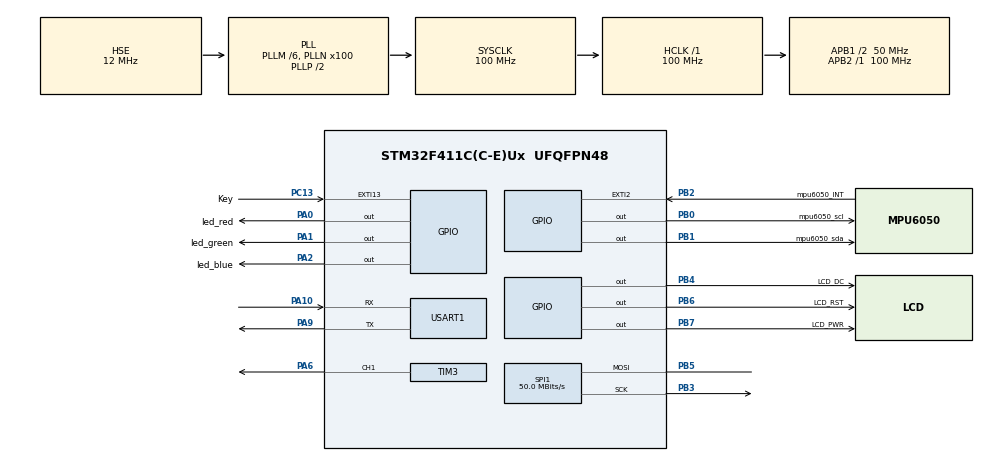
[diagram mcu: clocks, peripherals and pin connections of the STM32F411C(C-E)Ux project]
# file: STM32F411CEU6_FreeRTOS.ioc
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Dma.Request0=TIM3_CH1/TRIG
Dma.Request1=SPI1_TX
Dma.SPI1_TX.1.Direction=DMA_MEMORY_TO_PERIPH
Dma.SPI1_TX.1.FIFOMode=DMA_FIFOMODE_DISABLE
Dma.SPI1_TX.1.Instance=DMA2_Stream2
Dma.SPI1_TX.1.MemDataAlignment=DMA_MDATAALIGN_BYTE
Dma.SPI1_TX.1.MemInc=DMA_MINC_ENABLE
Dma.SPI1_TX.1.Mode=DMA_NORMAL
Dma.SPI1_TX.1.PeriphDataAlignment=DMA_PDATAALIGN_BYTE
Dma.SPI1_TX.1.PeriphInc=DMA_PINC_DISABLE
Dma.SPI1_TX.1.Priority=DMA_PRIORITY_LOW
Dma.TIM3_CH1/TRIG.0.Direction=DMA_MEMORY_TO_PERIPH
Dma.TIM3_CH1/TRIG.0.FIFOMode=DMA_FIFOMODE_DISABLE
Dma.TIM3_CH1/TRIG.0.Instance=DMA1_Stream4
Dma.TIM3_CH1/TRIG.0.MemDataAlignment=DMA_MDATAALIGN_WORD
Dma.TIM3_CH1/TRIG.0.MemInc=DMA_MINC_ENABLE
Dma.TIM3_CH1/TRIG.0.Mode=DMA_NORMAL
Dma.TIM3_CH1/TRIG.0.PeriphDataAlignment=DMA_PDATAALIGN_WORD
Dma.TIM3_CH1/TRIG.0.PeriphInc=DMA_PINC_DISABLE
Dma.TIM3_CH1/TRIG.0.Priority=DMA_PRIORITY_LOW
FREERTOS.Tasks01=Task_LED_Red,24,128,AppTask_LED_Red,Default,NULL,Dynamic,NULL,NULL;Task_LED_Green,8,128,AppTask_LED_Green,Default,NULL,Dynamic,NULL,NULL
Mcu.Family=STM32F4
Mcu.Name=STM32F411C(C-E)Ux
Mcu.Package=UFQFPN48
NVIC.DMA1_Stream4_IRQn=true\:5\:0\:false\:false\:true\:true\:false\:true\:true
NVIC.DMA2_Stream2_IRQn=true\:5\:0\:false\:false\:true\:true\:false\:true\:true
NVIC.EXTI15_10_IRQn=true\:6\:0\:true\:false\:true\:true\:true\:true\:true
NVIC.EXTI2_IRQn=true\:6\:0\:true\:false\:true\:true\:true\:true\:true
NVIC.PriorityGroup=NVIC_PRIORITYGROUP_4
NVIC.TIM1_TRG_COM_TIM11_IRQn=true\:5\:0\:false\:false\:true\:true\:true\:true\:true
NVIC.TIM4_IRQn=true\:0\:0\:false\:false\:true\:false\:false\:true\:true
NVIC.TimeBase=TIM4_IRQn
NVIC.TimeBaseIP=TIM4
PA0-WKUP.GPIO_Label=led_red
PA0-WKUP.GPIO_PuPd=GPIO_PULLUP
PA0-WKUP.PinState=GPIO_PIN_SET
PA0-WKUP.Signal=GPIO_Output
PA1.GPIO_Label=led_green
PA1.GPIO_ModeDefaultOutputPP=GPIO_MODE_OUTPUT_PP
PA1.GPIO_PuPd=GPIO_PULLUP
PA1.PinState=GPIO_PIN_SET
PA1.Signal=GPIO_Output
PA10.Mode=Asynchronous
PA10.Signal=USART1_RX
PA13.Mode=Serial_Wire
PA13.Signal=SYS_JTMS-SWDIO
PA14.Mode=Serial_Wire
PA14.Signal=SYS_JTCK-SWCLK
PA2.GPIO_Label=led_blue
PA2.GPIO_PuPd=GPIO_PULLUP
PA2.PinState=GPIO_PIN_SET
PA2.Signal=GPIO_Output
PA6.Signal=S_TIM3_CH1
PA9.Mode=Asynchronous
PA9.Signal=USART1_TX
PB0.GPIO_Label=mpu6050_scl
PB0.GPIO_ModeDefaultOutputPP=GPIO_MODE_OUTPUT_PP
PB0.GPIO_PuPd=GPIO_PULLUP
PB0.GPIO_Speed=GPIO_SPEED_FREQ_VERY_HIGH
PB0.PinState=GPIO_PIN_RESET
PB0.Signal=GPIO_Output
PB1.GPIO_Label=mpu6050_sda
PB1.GPIO_ModeDefaultOutputPP=GPIO_MODE_OUTPUT_OD
PB1.GPIO_PuPd=GPIO_PULLUP
PB1.GPIO_Speed=GPIO_SPEED_FREQ_VERY_HIGH
PB1.PinState=GPIO_PIN_RESET
PB1.Signal=GPIO_Output
PB2.GPIO_Label=mpu6050_INT
PB2.Signal=GPXTI2
PB3.Mode=Simplex_Bidirectional_Master
PB3.Signal=SPI1_SCK
PB4.GPIO_Label=LCD_DC
PB4.Signal=GPIO_Output
PB5.Mode=Simplex_Bidirectional_Master
PB5.Signal=SPI1_MOSI
PB6.GPIO_Label=LCD_RST
PB6.Signal=GPIO_Output
PB7.GPIO_Label=LCD_PWR
PB7.Signal=GPIO_Output
PC13-ANTI_TAMP.GPIO_Label=Key
PC13-ANTI_TAMP.GPIO_ModeDefaultEXTI=GPIO_MODE_IT_FALLING
PC13-ANTI_TAMP.GPIO_PuPd=GPIO_PULLUP
PC13-ANTI_TAMP.Signal=GPXTI13
PH0\ -\ OSC_IN.Mode=HSE-External-Oscillator
PH0\ -\ OSC_IN.Signal=RCC_OSC_IN
PH1\ -\ OSC_OUT.Mode=HSE-External-Oscillator
PH1\ -\ OSC_OUT.Signal=RCC_OSC_OUT
ProjectManager.HeapSize=0x200
ProjectManager.StackSize=0x400
ProjectManager.TargetToolchain=MDK-ARM V5.27
RCC.48MHZClocksFreq_Value=50000000
RCC.AHBFreq_Value=100000000
RCC.APB1CLKDivider=RCC_HCLK_DIV2
RCC.APB1Freq_Value=50000000
RCC.APB1TimFreq_Value=100000000
RCC.APB2Freq_Value=100000000
RCC.APB2TimFreq_Value=100000000
RCC.CortexFreq_Value=100000000
RCC.HCLKFreq_Value=100000000
RCC.HSE_VALUE=12000000
RCC.HSI_VALUE=16000000
RCC.LSE_VALUE=32768
RCC.PLLM=6
RCC.PLLN=100
RCC.PLLSourceVirtual=RCC_PLLSOURCE_HSE
RCC.SYSCLKFreq_VALUE=100000000
RCC.SYSCLKSource=RCC_SYSCLKSOURCE_PLLCLK
RCC.VCOOutputFreq_Value=200000000
SH.S_TIM3_CH1.0=TIM3_CH1,PWM Generation1 CH1
SPI1.CLKPhase=SPI_PHASE_2EDGE
SPI1.CLKPolarity=SPI_POLARITY_HIGH
SPI1.CalculateBaudRate=50.0 MBits/s
SPI1.Direction=SPI_DIRECTION_1LINE
SPI1.Mode=SPI_MODE_MASTER
SPI1.VirtualType=VM_MASTER
TIM10.Prescaler=100-1
TIM11.Period=100-1
TIM11.Prescaler=100-1
TIM3.Channel-PWM\ Generation1\ CH1=TIM_CHANNEL_1
TIM3.Period=125-1
USART1.VirtualMode=VM_ASYNC
VP_FREERTOS_VS_CMSIS_V2.Mode=CMSIS_V2
VP_SYS_VS_tim4.Mode=TIM4
VP_TIM10_VS_ClockSourceINT.Mode=Enable_Timer
VP_TIM11_VS_ClockSourceINT.Mode=Enable_Timer
VP_TIM3_VS_ClockSourceINT.Mode=Internal
board=custom

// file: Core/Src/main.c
/* USER CODE BEGIN Header */
/**
  ******************************************************************************
  * @file           : main.c
  * @brief          : Main program body
  ******************************************************************************
  * @attention
  *
  * <h2><center>&copy; Copyright (c) 2023 STMicroelectronics.
  * All rights reserved.</center></h2>
  *
  * This software component is licensed by ST under Ultimate Liberty license
  * SLA0044, the "License"; You may not use this file except in compliance with
  * the License. You may obtain a copy of the License at:
  *                             www.st.com/SLA0044
  *
  ******************************************************************************
  */
/* USER CODE END Header */
#include "main.h"
#include "cmsis_os.h"
#include "dma.h"
#include "spi.h"
#include "tim.h"
#include "usart.h"
#include "gpio.h"

void SystemClock_Config(void);
void MX_FREERTOS_Init(void);

int main(void)
{

  /* MCU Configuration--------------------------------------------------------*/

  /* Reset of all peripherals, Initializes the Flash interface and the Systick. */
  HAL_Init();

  /* Configure the system clock */
  SystemClock_Config();

  /* Initialize all configured peripherals */
  MX_GPIO_Init();
  MX_DMA_Init();
  MX_USART1_UART_Init();
  MX_TIM3_Init();
  MX_TIM11_Init();
  MX_SPI1_Init();
  MX_TIM10_Init();
  /* USER CODE BEGIN 2 */

	LCD_Init();
	LCD_Clear(BLACK);
	POINT_COLOR = RED;
	BACK_COLOR  = BLACK;
	LCD_ShowString(0, 0*32, strlen("FreeRTOS_DEMO2")*16, 32, 32, "FreeRTOS_DEMO1");
	LCD_ShowString(0, 1*32, strlen("Uart1 Printf ...")*12, 24, 24, "Uart1 Printf ...");

  /* USER CODE END 2 */

  /* Init scheduler */
  osKernelInitialize();  /* Call init function for freertos objects (in freertos.c) */
  MX_FREERTOS_Init();

  /* Start scheduler */
  osKernelStart();

  /* We should never get here as control is now taken by the scheduler */
  /* Infinite loop */
  while (1)
  {

  }
}

void SystemClock_Config(void)
{
  RCC_OscInitTypeDef RCC_OscInitStruct = {0};
  RCC_ClkInitTypeDef RCC_ClkInitStruct = {0};

  /** Configure the main internal regulator output voltage
  */
  __HAL_RCC_PWR_CLK_ENABLE();
  __HAL_PWR_VOLTAGESCALING_CONFIG(PWR_REGULATOR_VOLTAGE_SCALE1);

  /** Initializes the RCC Oscillators according to the specified parameters
  * in the RCC_OscInitTypeDef structure.
  */
  RCC_OscInitStruct.OscillatorType = RCC_OSCILLATORTYPE_HSE;
  RCC_OscInitStruct.HSEState = RCC_HSE_ON;
  RCC_OscInitStruct.PLL.PLLState = RCC_PLL_ON;
  RCC_OscInitStruct.PLL.PLLSource = RCC_PLLSOURCE_HSE;
  RCC_OscInitStruct.PLL.PLLM = 6;
  RCC_OscInitStruct.PLL.PLLN = 100;
  RCC_OscInitStruct.PLL.PLLP = RCC_PLLP_DIV2;
  RCC_OscInitStruct.PLL.PLLQ = 4;
  if (HAL_RCC_OscConfig(&RCC_OscInitStruct) != HAL_OK)
  {
    Error_Handler();
  }

  /** Initializes the CPU, AHB and APB buses clocks
  */
  RCC_ClkInitStruct.ClockType = RCC_CLOCKTYPE_HCLK|RCC_CLOCKTYPE_SYSCLK
                              |RCC_CLOCKTYPE_PCLK1|RCC_CLOCKTYPE_PCLK2;
  RCC_ClkInitStruct.SYSCLKSource = RCC_SYSCLKSOURCE_PLLCLK;
  RCC_ClkInitStruct.AHBCLKDivider = RCC_SYSCLK_DIV1;
  RCC_ClkInitStruct.APB1CLKDivider = RCC_HCLK_DIV2;
  RCC_ClkInitStruct.APB2CLKDivider = RCC_HCLK_DIV1;

  if (HAL_RCC_ClockConfig(&RCC_ClkInitStruct, FLASH_LATENCY_3) != HAL_OK)
  {
    Error_Handler();
  }
}

void HAL_TIM_PeriodElapsedCallback(TIM_HandleTypeDef *htim)
{
  if (htim->Instance == TIM4) {
    HAL_IncTick();
  }
  /* USER CODE BEGIN Callback 1 */
	else if (htim->Instance == TIM11)
	{
		FreeRTOSRunTimeTicks++;
  }
  /* USER CODE END Callback 1 */
}

void Error_Handler(void)
{
  __disable_irq();
  while (1)
  {
  }
}
